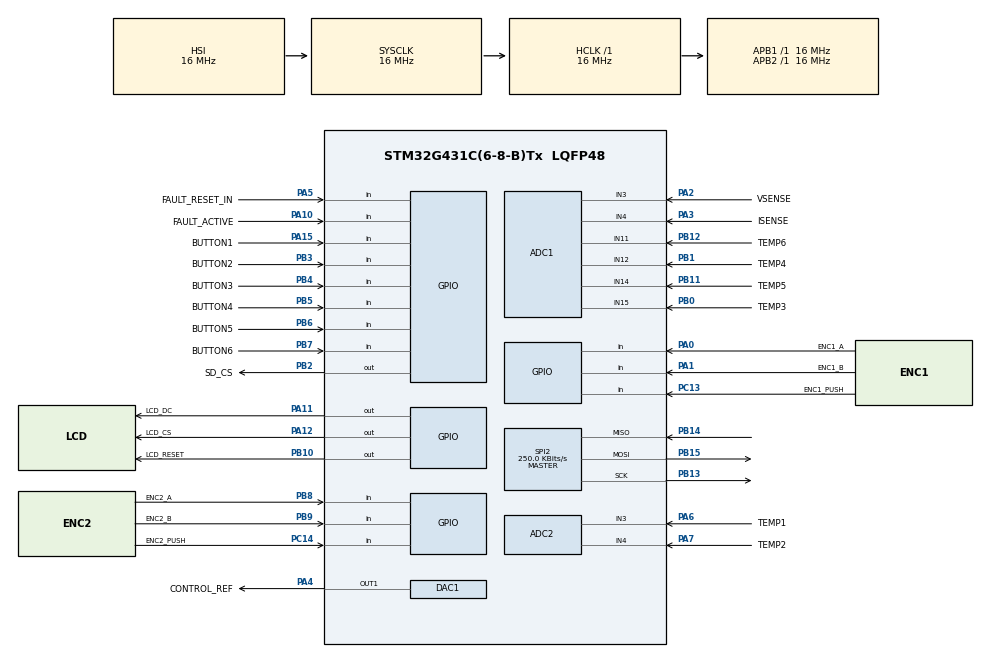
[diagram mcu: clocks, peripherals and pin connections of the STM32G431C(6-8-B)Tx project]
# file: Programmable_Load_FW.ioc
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ADC1.Channel-1\#ChannelRegularConversion=ADC_CHANNEL_3
ADC1.Channel-2\#ChannelRegularConversion=ADC_CHANNEL_4
ADC1.Channel-3\#ChannelRegularConversion=ADC_CHANNEL_15
ADC1.Channel-4\#ChannelRegularConversion=ADC_CHANNEL_12
ADC1.Channel-5\#ChannelRegularConversion=ADC_CHANNEL_14
ADC1.Channel-6\#ChannelRegularConversion=ADC_CHANNEL_11
ADC1.EOCSelection=ADC_EOC_SEQ_CONV
ADC1.NbrOfConversion=6
ADC1.NbrOfConversionFlag=1
ADC1.OffsetNumber-1\#ChannelRegularConversion=ADC_OFFSET_NONE
ADC1.OffsetNumber-2\#ChannelRegularConversion=ADC_OFFSET_NONE
ADC1.OffsetNumber-3\#ChannelRegularConversion=ADC_OFFSET_NONE
ADC1.OffsetNumber-4\#ChannelRegularConversion=ADC_OFFSET_NONE
ADC1.OffsetNumber-5\#ChannelRegularConversion=ADC_OFFSET_NONE
ADC1.OffsetNumber-6\#ChannelRegularConversion=ADC_OFFSET_NONE
ADC1.Rank-1\#ChannelRegularConversion=1
ADC1.Rank-2\#ChannelRegularConversion=2
ADC1.Rank-3\#ChannelRegularConversion=3
ADC1.Rank-4\#ChannelRegularConversion=4
ADC1.Rank-5\#ChannelRegularConversion=5
ADC1.Rank-6\#ChannelRegularConversion=6
ADC1.SamplingTime-1\#ChannelRegularConversion=ADC_SAMPLETIME_247CYCLES_5
ADC1.SamplingTime-2\#ChannelRegularConversion=ADC_SAMPLETIME_247CYCLES_5
ADC1.SamplingTime-3\#ChannelRegularConversion=ADC_SAMPLETIME_247CYCLES_5
ADC1.SamplingTime-4\#ChannelRegularConversion=ADC_SAMPLETIME_247CYCLES_5
ADC1.SamplingTime-5\#ChannelRegularConversion=ADC_SAMPLETIME_247CYCLES_5
ADC1.SamplingTime-6\#ChannelRegularConversion=ADC_SAMPLETIME_247CYCLES_5
ADC1.master=1
ADC2.Channel-2\#ChannelRegularConversion=ADC_CHANNEL_3
ADC2.Channel-3\#ChannelRegularConversion=ADC_CHANNEL_4
ADC2.EOCSelection=ADC_EOC_SEQ_CONV
ADC2.NbrOfConversion=2
ADC2.NbrOfConversionFlag=1
ADC2.OffsetNumber-2\#ChannelRegularConversion=ADC_OFFSET_NONE
ADC2.OffsetNumber-3\#ChannelRegularConversion=ADC_OFFSET_NONE
ADC2.Rank-2\#ChannelRegularConversion=1
ADC2.Rank-3\#ChannelRegularConversion=2
ADC2.SamplingTime-2\#ChannelRegularConversion=ADC_SAMPLETIME_247CYCLES_5
ADC2.SamplingTime-3\#ChannelRegularConversion=ADC_SAMPLETIME_247CYCLES_5
Dma.ADC1.0.Direction=DMA_PERIPH_TO_MEMORY
Dma.ADC1.0.EventEnable=DISABLE
Dma.ADC1.0.Instance=DMA1_Channel1
Dma.ADC1.0.MemDataAlignment=DMA_MDATAALIGN_HALFWORD
Dma.ADC1.0.MemInc=DMA_MINC_ENABLE
Dma.ADC1.0.Mode=DMA_NORMAL
Dma.ADC1.0.PeriphDataAlignment=DMA_PDATAALIGN_HALFWORD
Dma.ADC1.0.PeriphInc=DMA_PINC_DISABLE
Dma.ADC1.0.Polarity=HAL_DMAMUX_REQ_GEN_RISING
Dma.ADC1.0.Priority=DMA_PRIORITY_LOW
Dma.ADC1.0.RequestNumber=1
Dma.ADC1.0.SignalID=NONE
Dma.ADC1.0.SyncEnable=DISABLE
Dma.ADC1.0.SyncPolarity=HAL_DMAMUX_SYNC_NO_EVENT
Dma.ADC1.0.SyncRequestNumber=1
Dma.ADC1.0.SyncSignalID=NONE
Dma.ADC2.1.Direction=DMA_PERIPH_TO_MEMORY
Dma.ADC2.1.EventEnable=DISABLE
Dma.ADC2.1.Instance=DMA1_Channel2
Dma.ADC2.1.MemDataAlignment=DMA_MDATAALIGN_HALFWORD
Dma.ADC2.1.MemInc=DMA_MINC_ENABLE
Dma.ADC2.1.Mode=DMA_NORMAL
Dma.ADC2.1.PeriphDataAlignment=DMA_PDATAALIGN_HALFWORD
Dma.ADC2.1.PeriphInc=DMA_PINC_DISABLE
Dma.ADC2.1.Polarity=HAL_DMAMUX_REQ_GEN_RISING
Dma.ADC2.1.Priority=DMA_PRIORITY_LOW
Dma.ADC2.1.RequestNumber=1
Dma.ADC2.1.SignalID=NONE
Dma.ADC2.1.SyncEnable=DISABLE
Dma.ADC2.1.SyncPolarity=HAL_DMAMUX_SYNC_NO_EVENT
Dma.ADC2.1.SyncRequestNumber=1
Dma.ADC2.1.SyncSignalID=NONE
Dma.Request0=ADC1
Dma.Request1=ADC2
Mcu.Family=STM32G4
Mcu.Name=STM32G431C(6-8-B)Tx
Mcu.Package=LQFP48
NVIC.DMA1_Channel1_IRQn=true\:0\:0\:false\:false\:true\:false\:true\:true
NVIC.DMA1_Channel2_IRQn=true\:0\:0\:false\:false\:true\:false\:true\:true
NVIC.PriorityGroup=NVIC_PRIORITYGROUP_4
PA0.GPIO_Label=ENC1_A
PA0.Signal=GPIO_Input
PA1.GPIO_Label=ENC1_B
PA1.Signal=GPIO_Input
PA10.GPIO_Label=FAULT_ACTIVE
PA10.Signal=GPIO_Input
PA11.GPIO_Label=LCD_DC
PA11.Signal=GPIO_Output
PA12.GPIO_Label=LCD_CS
PA12.PinState=GPIO_PIN_SET
PA12.Signal=GPIO_Output
PA13.GPIO_Label=SWD_IO
PA13.Mode=Serial_Wire
PA13.Signal=SYS_JTMS-SWDIO
PA14.GPIO_Label=SW_CLK
PA14.Mode=Serial_Wire
PA14.Signal=SYS_JTCK-SWCLK
PA15.GPIO_Label=BUTTON1
PA15.Signal=GPIO_Input
PA2.GPIO_Label=VSENSE
PA2.Mode=IN3-Single-Ended
PA2.Signal=ADC1_IN3
PA3.GPIO_Label=ISENSE
PA3.Mode=IN4-Single-Ended
PA3.Signal=ADC1_IN4
PA4.GPIO_Label=CONTROL_REF
PA4.Signal=COMP_DAC11_group
PA5.GPIO_Label=FAULT_RESET_IN
PA5.Signal=GPIO_Input
PA6.GPIO_Label=TEMP1
PA6.Mode=IN3-Single-Ended
PA6.Signal=ADC2_IN3
PA7.GPIO_Label=TEMP2
PA7.Mode=IN4-Single-Ended
PA7.Signal=ADC2_IN4
PB0.GPIO_Label=TEMP3
PB0.Mode=IN15-Single-Ended
PB0.Signal=ADC1_IN15
PB1.GPIO_Label=TEMP4
PB1.Mode=IN12-Single-Ended
PB1.Signal=ADC1_IN12
PB10.GPIO_Label=LCD_RESET
PB10.PinState=GPIO_PIN_SET
PB10.Signal=GPIO_Output
PB11.GPIO_Label=TEMP5
PB11.Mode=IN14-Single-Ended
PB11.Signal=ADC1_IN14
PB12.GPIO_Label=TEMP6
PB12.Mode=IN11-Single-Ended
PB12.Signal=ADC1_IN11
PB13.Mode=Full_Duplex_Master
PB13.Signal=SPI2_SCK
PB14.GPIO_PuPd=GPIO_PULLUP
PB14.Mode=Full_Duplex_Master
PB14.Signal=SPI2_MISO
PB15.Mode=Full_Duplex_Master
PB15.Signal=SPI2_MOSI
PB2.GPIO_Label=SD_CS
PB2.PinState=GPIO_PIN_SET
PB2.Signal=GPIO_Output
PB3.GPIO_Label=BUTTON2
PB3.Signal=GPIO_Input
PB4.GPIO_Label=BUTTON3
PB4.Signal=GPIO_Input
PB5.GPIO_Label=BUTTON4
PB5.Signal=GPIO_Input
PB6.GPIO_Label=BUTTON5
PB6.Signal=GPIO_Input
PB7.GPIO_Label=BUTTON6
PB7.Signal=GPIO_Input
PB8-BOOT0.GPIO_Label=ENC2_A
PB8-BOOT0.Signal=GPIO_Input
PB9.GPIO_Label=ENC2_B
PB9.Signal=GPIO_Input
PC13.GPIO_Label=ENC1_PUSH
PC13.Signal=GPIO_Input
PC14-OSC32_IN.GPIO_Label=ENC2_PUSH
PC14-OSC32_IN.Signal=GPIO_Input
ProjectManager.HeapSize=0x200
ProjectManager.StackSize=0x400
ProjectManager.TargetToolchain=STM32CubeIDE
RCC.AHBFreq_Value=16000000
RCC.APB1Freq_Value=16000000
RCC.APB1TimFreq_Value=16000000
RCC.APB2Freq_Value=16000000
RCC.APB2TimFreq_Value=16000000
RCC.CortexFreq_Value=16000000
RCC.EXTERNAL_CLOCK_VALUE=12288000
RCC.HCLKFreq_Value=16000000
RCC.HSE_VALUE=8000000
RCC.HSI48_VALUE=48000000
RCC.HSI_VALUE=16000000
RCC.LSE_VALUE=32768
RCC.SYSCLKFreq_VALUE=16000000
RCC.USBFreq_Value=64000000
RCC.VCOOutputFreq_Value=128000000
SH.COMP_DAC11_group.0=DAC1_OUT1,DAC_OUT1
SPI2.BaudRatePrescaler=SPI_BAUDRATEPRESCALER_64
SPI2.CalculateBaudRate=250.0 KBits/s
SPI2.DataSize=SPI_DATASIZE_8BIT
SPI2.Direction=SPI_DIRECTION_2LINES
SPI2.Mode=SPI_MODE_MASTER
SPI2.VirtualType=VM_MASTER
VP_SYS_VS_DBSignals.Mode=DisableDeadBatterySignals
board=custom

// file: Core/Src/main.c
/* USER CODE BEGIN Header */
/**
  ******************************************************************************
  * @file           : main.c
  * @brief          : Main program body
  ******************************************************************************
  * @attention
  *
  * Copyright (c) 2026 STMicroelectronics.
  * All rights reserved.
  *
  * This software is licensed under terms that can be found in the LICENSE file
  * in the root directory of this software component.
  * If no LICENSE file comes with this software, it is provided AS-IS.
  *
  ******************************************************************************
  */
/* USER CODE END Header */
#include "main.h"
#include "adc.h"
#include "dac.h"
#include "dma.h"
#include "spi.h"
#include "gpio.h"

/* USER CODE BEGIN Includes */

#include "load_control.h"
#include "discharge_session.h"
#include "ui.h"

/* USER CODE END Includes */

void SystemClock_Config(void);

int main(void)
{

  /* MCU Configuration--------------------------------------------------------*/

  /* Reset of all peripherals, Initializes the Flash interface and the Systick. */
  HAL_Init();

  /* Configure the system clock */
  SystemClock_Config();

  /* Initialize all configured peripherals */
  MX_GPIO_Init();
  MX_DMA_Init();
  MX_ADC1_Init();
  MX_ADC2_Init();
  MX_DAC1_Init();
  MX_SPI2_Init();
  /* USER CODE BEGIN 2 */
  /* Deselect the SD card because it shares SPI2. */
  HAL_GPIO_WritePin(SD_CS_GPIO_Port, SD_CS_Pin, GPIO_PIN_SET);

  if (LoadControl_Init() != HAL_OK)
      Error_Handler();
  UI_Init();
  Discharge_Init();

  /* USER CODE END 2 */

  /* Infinite loop */
  while (1)
  {

    /* USER CODE BEGIN 3 */
      LoadControl_Process();
      Discharge_Process();
      UI_Task();
      LoadControl_Process();
  }
  /* USER CODE END 3 */
}

void SystemClock_Config(void)
{
  RCC_OscInitTypeDef RCC_OscInitStruct = {0};
  RCC_ClkInitTypeDef RCC_ClkInitStruct = {0};

  /** Configure the main internal regulator output voltage
  */
  HAL_PWREx_ControlVoltageScaling(PWR_REGULATOR_VOLTAGE_SCALE1);

  /** Initializes the RCC Oscillators according to the specified parameters
  * in the RCC_OscInitTypeDef structure.
  */
  RCC_OscInitStruct.OscillatorType = RCC_OSCILLATORTYPE_HSI;
  RCC_OscInitStruct.HSIState = RCC_HSI_ON;
  RCC_OscInitStruct.HSICalibrationValue = RCC_HSICALIBRATION_DEFAULT;
  RCC_OscInitStruct.PLL.PLLState = RCC_PLL_NONE;
  if (HAL_RCC_OscConfig(&RCC_OscInitStruct) != HAL_OK)
  {
    Error_Handler();
  }

  /** Initializes the CPU, AHB and APB buses clocks
  */
  RCC_ClkInitStruct.ClockType = RCC_CLOCKTYPE_HCLK|RCC_CLOCKTYPE_SYSCLK
                              |RCC_CLOCKTYPE_PCLK1|RCC_CLOCKTYPE_PCLK2;
  RCC_ClkInitStruct.SYSCLKSource = RCC_SYSCLKSOURCE_HSI;
  RCC_ClkInitStruct.AHBCLKDivider = RCC_SYSCLK_DIV1;
  RCC_ClkInitStruct.APB1CLKDivider = RCC_HCLK_DIV1;
  RCC_ClkInitStruct.APB2CLKDivider = RCC_HCLK_DIV1;

  if (HAL_RCC_ClockConfig(&RCC_ClkInitStruct, FLASH_LATENCY_0) != HAL_OK)
  {
    Error_Handler();
  }
}

void Error_Handler(void)
{
  /* USER CODE BEGIN Error_Handler_Debug */
  /* User can add his own implementation to report the HAL error return state */
  LoadControl_EmergencyZero();
  __disable_irq();
  while (1)
  {
  }
  /* USER CODE END Error_Handler_Debug */
}
